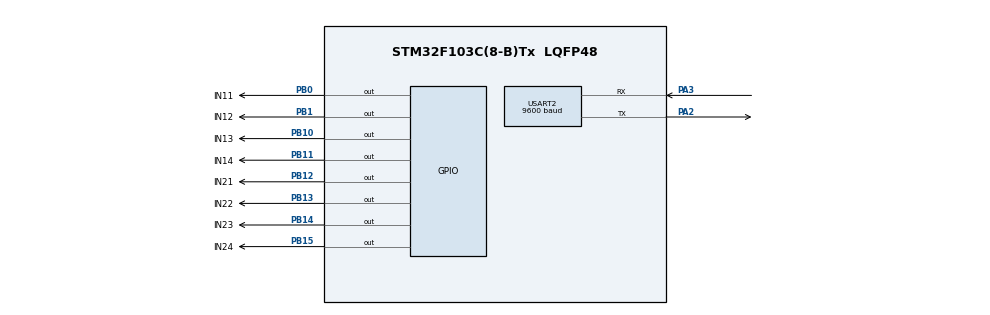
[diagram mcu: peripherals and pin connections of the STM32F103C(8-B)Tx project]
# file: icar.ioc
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Mcu.Family=STM32F1
Mcu.Name=STM32F103C(8-B)Tx
Mcu.Package=LQFP48
NVIC.PriorityGroup=NVIC_PRIORITYGROUP_4
NVIC.USART2_IRQn=true\:0\:0\:false\:false\:true\:true\:true\:true
PA2.Mode=Asynchronous
PA2.Signal=USART2_TX
PA3.Mode=Asynchronous
PA3.Signal=USART2_RX
PB0.GPIO_Label=IN11
PB0.GPIO_Speed=GPIO_SPEED_FREQ_HIGH
PB0.Signal=GPIO_Output
PB1.GPIO_Label=IN12
PB1.GPIO_Speed=GPIO_SPEED_FREQ_HIGH
PB1.Signal=GPIO_Output
PB10.GPIO_Label=IN13
PB10.GPIO_Speed=GPIO_SPEED_FREQ_HIGH
PB10.Signal=GPIO_Output
PB11.GPIO_Label=IN14
PB11.GPIO_Speed=GPIO_SPEED_FREQ_HIGH
PB11.Signal=GPIO_Output
PB12.GPIO_Label=IN21
PB12.GPIO_Speed=GPIO_SPEED_FREQ_HIGH
PB12.Signal=GPIO_Output
PB13.GPIO_Label=IN22
PB13.GPIO_Speed=GPIO_SPEED_FREQ_HIGH
PB13.Signal=GPIO_Output
PB14.GPIO_Label=IN23
PB14.GPIO_Speed=GPIO_SPEED_FREQ_HIGH
PB14.Signal=GPIO_Output
PB15.GPIO_Label=IN24
PB15.GPIO_Speed=GPIO_SPEED_FREQ_HIGH
PB15.Signal=GPIO_Output
ProjectManager.HeapSize=0x200
ProjectManager.StackSize=0x400
ProjectManager.TargetToolchain=STM32CubeIDE
RCC.APB1Freq_Value=8000000
RCC.APB2Freq_Value=8000000
USART2.BaudRate=9600
USART2.VirtualMode=VM_ASYNC
VP_SYS_VS_ND.Mode=No_Debug
board=custom

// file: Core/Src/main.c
/* USER CODE BEGIN Header */
/**
  ******************************************************************************
  * @file           : main.c
  * @brief          : Main program body
  ******************************************************************************
  * @attention
  *
  * Copyright (c) 2023 STMicroelectronics.
  * All rights reserved.
  *
  * This software is licensed under terms that can be found in the LICENSE file
  * in the root directory of this software component.
  * If no LICENSE file comes with this software, it is provided AS-IS.
  *
  ******************************************************************************
  */
/* USER CODE END Header */
#include "main.h"

/* USER CODE BEGIN Includes */
#include "car.h"

/* USER CODE END Includes */

UART_HandleTypeDef huart2;

/* USER CODE BEGIN PV */
uint8_t rx_buf = CAR_STOP;
uint8_t rx_status = 0;
/* USER CODE END PV */

void SystemClock_Config(void);
static void MX_GPIO_Init(void);
static void MX_USART2_UART_Init(void);

/* USER CODE BEGIN 0 */
void HAL_UART_RxCpltCallback(UART_HandleTypeDef *huart) {
  rx_status = 1;
  rx_buf = huart->Instance->DR;
  HAL_UART_Receive_IT(huart, &rx_buf, 1);
}
/* USER CODE END 0 */

int main(void)
{

  /* MCU Configuration--------------------------------------------------------*/

  /* Reset of all peripherals, Initializes the Flash interface and the Systick. */
  HAL_Init();

  /* Configure the system clock */
  SystemClock_Config();

  /* Initialize all configured peripherals */
  MX_GPIO_Init();
  MX_USART2_UART_Init();
  /* USER CODE BEGIN 2 */
  struct Car car = Car_Init();
  HAL_UART_Receive_IT(&huart2, &rx_buf, 1);
  /* USER CODE END 2 */

  /* Infinite loop */
  /* USER CODE BEGIN WHILE */
  while (1)
  {
    if (rx_status) {
      rx_status = 0;
      car.set_control(&car, rx_buf);
    }
    car.update(&car);
    /* USER CODE END WHILE */

  }
}

void SystemClock_Config(void)
{
  RCC_OscInitTypeDef RCC_OscInitStruct = {0};
  RCC_ClkInitTypeDef RCC_ClkInitStruct = {0};

  /** Initializes the RCC Oscillators according to the specified parameters
  * in the RCC_OscInitTypeDef structure.
  */
  RCC_OscInitStruct.OscillatorType = RCC_OSCILLATORTYPE_HSI;
  RCC_OscInitStruct.HSIState = RCC_HSI_ON;
  RCC_OscInitStruct.HSICalibrationValue = RCC_HSICALIBRATION_DEFAULT;
  RCC_OscInitStruct.PLL.PLLState = RCC_PLL_NONE;
  if (HAL_RCC_OscConfig(&RCC_OscInitStruct) != HAL_OK)
  {
    Error_Handler();
  }

  /** Initializes the CPU, AHB and APB buses clocks
  */
  RCC_ClkInitStruct.ClockType = RCC_CLOCKTYPE_HCLK|RCC_CLOCKTYPE_SYSCLK
                              |RCC_CLOCKTYPE_PCLK1|RCC_CLOCKTYPE_PCLK2;
  RCC_ClkInitStruct.SYSCLKSource = RCC_SYSCLKSOURCE_HSI;
  RCC_ClkInitStruct.AHBCLKDivider = RCC_SYSCLK_DIV1;
  RCC_ClkInitStruct.APB1CLKDivider = RCC_HCLK_DIV1;
  RCC_ClkInitStruct.APB2CLKDivider = RCC_HCLK_DIV1;

  if (HAL_RCC_ClockConfig(&RCC_ClkInitStruct, FLASH_LATENCY_0) != HAL_OK)
  {
    Error_Handler();
  }
}

static void MX_USART2_UART_Init(void)
{

  huart2.Instance = USART2;
  huart2.Init.BaudRate = 9600;
  huart2.Init.WordLength = UART_WORDLENGTH_8B;
  huart2.Init.StopBits = UART_STOPBITS_1;
  huart2.Init.Parity = UART_PARITY_NONE;
  huart2.Init.Mode = UART_MODE_TX_RX;
  huart2.Init.HwFlowCtl = UART_HWCONTROL_NONE;
  huart2.Init.OverSampling = UART_OVERSAMPLING_16;
  if (HAL_UART_Init(&huart2) != HAL_OK)
  {
    Error_Handler();
  }

}

static void MX_GPIO_Init(void)
{
  GPIO_InitTypeDef GPIO_InitStruct = {0};

  /* GPIO Ports Clock Enable */
  __HAL_RCC_GPIOA_CLK_ENABLE();
  __HAL_RCC_GPIOB_CLK_ENABLE();

  /*Configure GPIO pin Output Level */
  HAL_GPIO_WritePin(GPIOB, IN11_Pin|IN12_Pin|IN13_Pin|IN14_Pin
                          |IN21_Pin|IN22_Pin|IN23_Pin|IN24_Pin, GPIO_PIN_RESET);

  /*Configure GPIO pins : IN11_Pin IN12_Pin IN13_Pin IN14_Pin
                           IN21_Pin IN22_Pin IN23_Pin IN24_Pin */
  GPIO_InitStruct.Pin = IN11_Pin|IN12_Pin|IN13_Pin|IN14_Pin
                          |IN21_Pin|IN22_Pin|IN23_Pin|IN24_Pin;
  GPIO_InitStruct.Mode = GPIO_MODE_OUTPUT_PP;
  GPIO_InitStruct.Pull = GPIO_NOPULL;
  GPIO_InitStruct.Speed = GPIO_SPEED_FREQ_HIGH;
  HAL_GPIO_Init(GPIOB, &GPIO_InitStruct);

}

void Error_Handler(void)
{
  __disable_irq();
  while (1)
  {
  }
}
